# MAILBOX register map
Vendor: Texas Instruments
Peripheral module from a debugger description file (folder radar).
Registers are 32-bit, write-only, no defined reset value unless marked. A register's access mark holds for its fields unless they carry their own. Offsets are as the file gives them; lines under a group give offsets from that group; [hi:lo] are bit positions; {n}, {i} and the like mark numbered series; 'fields as' and 'values as' point back to an identical list; <NAME> marks a mode.

## MAILBOX
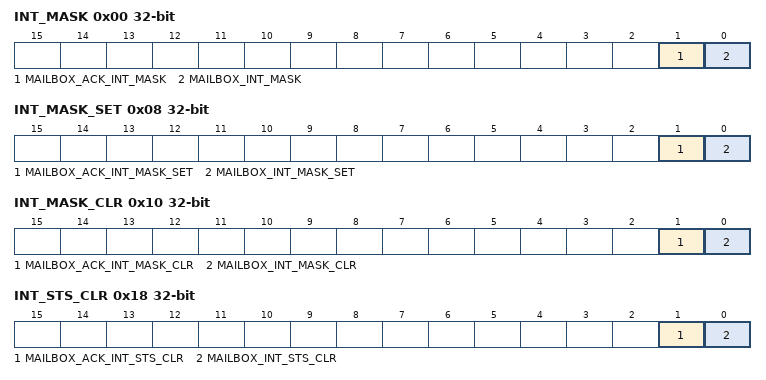
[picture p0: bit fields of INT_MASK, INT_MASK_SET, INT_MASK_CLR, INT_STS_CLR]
0x00 INT_MASK rw
  [1] MAILBOX_ACK_INT_MASK — Setting '1' to the bit will mask the interrupt and setting '0' will umask the interrupt.
  [0] MAILBOX_INT_MASK — Setting '1' to the bit will mask the interrupt and setting '0' will umask the interrupt.
0x08 INT_MASK_SET
  [1] MAILBOX_ACK_INT_MASK_SET — Writing '1' to the bit will set the mask corresponding interrupt. Writing '0' have no effect.
  [0] MAILBOX_INT_MASK_SET — Writing '1' to the bit will set the mask corresponding interrupt. Writing '0' have no effect.
0x10 INT_MASK_CLR
  [1] MAILBOX_ACK_INT_MASK_CLR — Writing '1' to the bit will clear the mask for the corresponding interrupt. Writing '0' have no effect.
  [0] MAILBOX_INT_MASK_CLR — Writing '1' to the bit will clear the mask for the corresponding interrupt. Writing '0' have no effect.
0x18 INT_STS_CLR
  [1] MAILBOX_ACK_INT_STS_CLR — Writing to this register with any value will clear the status register.
  [0] MAILBOX_INT_STS_CLR — Writing to this register with any value will clear the status register.
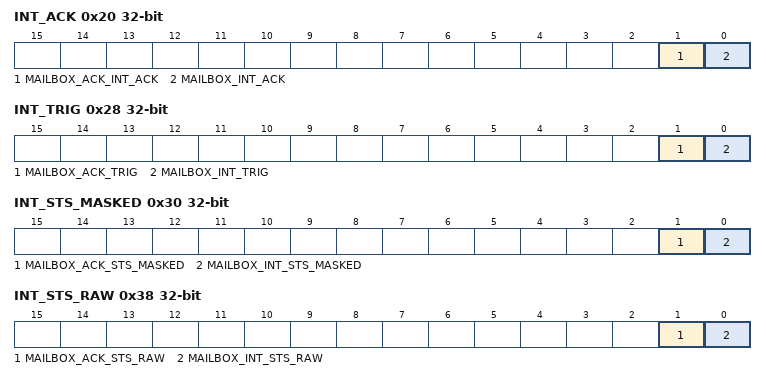
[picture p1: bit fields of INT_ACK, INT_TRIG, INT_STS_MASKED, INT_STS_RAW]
0x20 INT_ACK
  [1] MAILBOX_ACK_INT_ACK — Writing '1' to will clear the corresponding bit in status register. Writing '0' have no effect.
  [0] MAILBOX_INT_ACK — Writing '1' to will clear the corresponding bit in status register. Writing '0' have no effect.
0x28 INT_TRIG
  [1] MAILBOX_ACK_TRIG — writing '1' to this bit indicates to other sytem that read from mailbox is complete.
  [0] MAILBOX_INT_TRIG — Writing '1' to will trigger interrupt and also will set the corresponding bit in status register. Writing '0' have no effect.
0x30 INT_STS_MASKED ro
  [1] MAILBOX_ACK_STS_MASKED — Gives the current status of mailbox empty interrupt if it is not masked.
  [0] MAILBOX_INT_STS_MASKED — Gives the current status of mailbox full interrupt if it is not masked.
0x38 INT_STS_RAW ro
  [1] MAILBOX_ACK_STS_RAW — Gives the current status of mailbox empty interrupt
  [0] MAILBOX_INT_STS_RAW — Gives the current status of mailbox full interrupt
